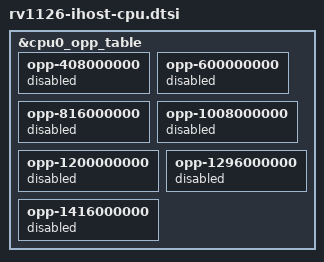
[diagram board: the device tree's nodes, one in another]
&cpu0_opp_table {
    opp-408000000 {
	    status = "disabled";
    };
    opp-600000000 {
	    status = "disabled";
    };
    opp-816000000 {
	    status = "disabled";
    };
    opp-1008000000 {
	    status = "disabled";
    };
    opp-1200000000 {
	    status = "disabled";
    };
    opp-1296000000 {
	    status = "disabled";
    };
    opp-1416000000 {
	    status = "disabled";
    };
};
